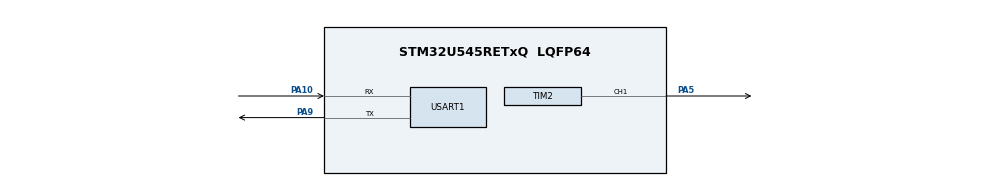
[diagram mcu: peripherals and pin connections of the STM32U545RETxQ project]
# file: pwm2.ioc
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CORTEX_M33_NS.userName=CORTEX_M33
Mcu.Family=STM32U5
Mcu.Name=STM32U545RETxQ
Mcu.Package=LQFP64
NVIC.PriorityGroup=NVIC_PRIORITYGROUP_4
PA10.Mode=Asynchronous
PA10.Signal=USART1_RX
PA5.Signal=S_TIM2_CH1
PA9.Mode=Asynchronous
PA9.Signal=USART1_TX
PWR.PowerMode=PWR_SMPS_SUPPLY
ProjectManager.HeapSize=0x200
ProjectManager.StackSize=0x400
ProjectManager.TargetToolchain=STM32CubeIDE
RCC.ADCFreq_Value=16000000
RCC.DACCLockSelectionVirtual=RCC_DAC1CLKSOURCE_LSI
RCC.DACCLockSelectionVirtualString=RCC_DAC1CLKSOURCE_LSI
RCC.EPOD_VALUE=4000000
RCC.HSE_VALUE=16000000
RCC.HSI48_VALUE=48000000
RCC.HSI_VALUE=16000000
RCC.LSE_VALUE=32768
RCC.LSIDIV_VALUE=32000
RCC.MSI_VALUE=4000000
RCC.USBFreq_Value=48000000
RCC.VCOOutputFreq_Value=516000000
SH.S_TIM2_CH1.0=TIM2_CH1,PWM Generation1 CH1
TIM2.AutoReloadPreload=TIM_AUTORELOAD_PRELOAD_DISABLE
TIM2.Channel-PWM\ Generation1\ CH1=TIM_CHANNEL_1
TIM2.PeriodNoDither=1000-1
TIM2.Prescaler=4-1
TIM2.PulseNoDither_1=0
USART1.VirtualMode-Asynchronous=VM_ASYNC
VP_ICACHE_VS_ICACHE.Mode=DirectMappedCache
VP_LPBAMQUEUE_VS_QUEUE.Mode=QUEUEMODE
VP_MEMORYMAP_VS_MEMORYMAP.Mode=CurAppReg
VP_NUCLEO-U545RE-Q_VS_BSP_COMMON.Mode=COMMON
VP_PWR_VS_LPOM.Mode=PowerOptimisation
VP_PWR_VS_SECSignals.Mode=Security/Privilege
VP_TIM2_VS_ClockSourceINT.Mode=Internal
board=NUCLEO-U545RE-Q

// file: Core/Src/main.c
/* USER CODE BEGIN Header */
/**
  ******************************************************************************
  * @file           : main.c
  * @brief          : Main program body
  ******************************************************************************
  * @attention
  *
  * Copyright (c) 2026 STMicroelectronics.
  * All rights reserved.
  *
  * This software is licensed under terms that can be found in the LICENSE file
  * in the root directory of this software component.
  * If no LICENSE file comes with this software, it is provided AS-IS.
  *
  ******************************************************************************
  */
/* USER CODE END Header */
#include "main.h"

TIM_HandleTypeDef htim2;

UART_HandleTypeDef huart1;

void SystemClock_Config(void);
static void SystemPower_Config(void);
static void MX_GPIO_Init(void);
static void MX_ICACHE_Init(void);
static void MX_USART1_UART_Init(void);
static void MX_TIM2_Init(void);

int main(void)
{

  /* MCU Configuration--------------------------------------------------------*/

  /* Reset of all peripherals, Initializes the Flash interface and the Systick. */
  HAL_Init();

  /* Configure the System Power */
  SystemPower_Config();

  /* Configure the system clock */
  SystemClock_Config();

  /* Initialize all configured peripherals */
  MX_GPIO_Init();
  MX_ICACHE_Init();
  MX_USART1_UART_Init();
  MX_TIM2_Init();
  /* USER CODE BEGIN 2 */
  HAL_TIM_PWM_Start(&htim2, TIM_CHANNEL_1);  // start PWM
  uint32_t maxPulse = htim2.Init.Period;  // = 999

  /* USER CODE END 2 */

  /* Infinite loop */
  /* USER CODE BEGIN WHILE */
  while (1)
  {
	  for (uint32_t pulse = 0; pulse <= maxPulse; pulse++)
	  {
		  __HAL_TIM_SET_COMPARE(&htim2, TIM_CHANNEL_1, pulse);
		  HAL_Delay(1);  // 1 ms per step → fade di ~1 s
	  }

    /* USER CODE END WHILE */

  }
}

void SystemClock_Config(void)
{
  RCC_OscInitTypeDef RCC_OscInitStruct = {0};
  RCC_ClkInitTypeDef RCC_ClkInitStruct = {0};

  /** Configure the main internal regulator output voltage
  */
  if (HAL_PWREx_ControlVoltageScaling(PWR_REGULATOR_VOLTAGE_SCALE4) != HAL_OK)
  {
    Error_Handler();
  }

  /** Initializes the CPU, AHB and APB buses clocks
  */
  RCC_OscInitStruct.OscillatorType = RCC_OSCILLATORTYPE_MSI;
  RCC_OscInitStruct.MSIState = RCC_MSI_ON;
  RCC_OscInitStruct.MSICalibrationValue = RCC_MSICALIBRATION_DEFAULT;
  RCC_OscInitStruct.MSIClockRange = RCC_MSIRANGE_4;
  RCC_OscInitStruct.PLL.PLLState = RCC_PLL_NONE;
  if (HAL_RCC_OscConfig(&RCC_OscInitStruct) != HAL_OK)
  {
    Error_Handler();
  }

  /** Initializes the CPU, AHB and APB buses clocks
  */
  RCC_ClkInitStruct.ClockType = RCC_CLOCKTYPE_HCLK|RCC_CLOCKTYPE_SYSCLK
                              |RCC_CLOCKTYPE_PCLK1|RCC_CLOCKTYPE_PCLK2
                              |RCC_CLOCKTYPE_PCLK3;
  RCC_ClkInitStruct.SYSCLKSource = RCC_SYSCLKSOURCE_MSI;
  RCC_ClkInitStruct.AHBCLKDivider = RCC_SYSCLK_DIV1;
  RCC_ClkInitStruct.APB1CLKDivider = RCC_HCLK_DIV1;
  RCC_ClkInitStruct.APB2CLKDivider = RCC_HCLK_DIV1;
  RCC_ClkInitStruct.APB3CLKDivider = RCC_HCLK_DIV1;

  if (HAL_RCC_ClockConfig(&RCC_ClkInitStruct, FLASH_LATENCY_0) != HAL_OK)
  {
    Error_Handler();
  }
}

/**
  * @brief Power Configuration
  * @retval None
  */
static void SystemPower_Config(void)
{

  /*
   * Switch to SMPS regulator instead of LDO
   */
  if (HAL_PWREx_ConfigSupply(PWR_SMPS_SUPPLY) != HAL_OK)
  {
    Error_Handler();
  }
}

static void MX_ICACHE_Init(void)
{

  /** Enable instruction cache in 1-way (direct mapped cache)
  */
  if (HAL_ICACHE_ConfigAssociativityMode(ICACHE_1WAY) != HAL_OK)
  {
    Error_Handler();
  }
  if (HAL_ICACHE_Enable() != HAL_OK)
  {
    Error_Handler();
  }

}

static void MX_TIM2_Init(void)
{

  TIM_ClockConfigTypeDef sClockSourceConfig = {0};
  TIM_MasterConfigTypeDef sMasterConfig = {0};
  TIM_OC_InitTypeDef sConfigOC = {0};

  htim2.Instance = TIM2;
  htim2.Init.Prescaler = 4-1;
  htim2.Init.CounterMode = TIM_COUNTERMODE_UP;
  htim2.Init.Period = 999;
  htim2.Init.ClockDivision = TIM_CLOCKDIVISION_DIV1;
  htim2.Init.AutoReloadPreload = TIM_AUTORELOAD_PRELOAD_DISABLE;
  if (HAL_TIM_Base_Init(&htim2) != HAL_OK)
  {
    Error_Handler();
  }
  sClockSourceConfig.ClockSource = TIM_CLOCKSOURCE_INTERNAL;
  if (HAL_TIM_ConfigClockSource(&htim2, &sClockSourceConfig) != HAL_OK)
  {
    Error_Handler();
  }
  if (HAL_TIM_PWM_Init(&htim2) != HAL_OK)
  {
    Error_Handler();
  }
  sMasterConfig.MasterOutputTrigger = TIM_TRGO_RESET;
  sMasterConfig.MasterSlaveMode = TIM_MASTERSLAVEMODE_DISABLE;
  if (HAL_TIMEx_MasterConfigSynchronization(&htim2, &sMasterConfig) != HAL_OK)
  {
    Error_Handler();
  }
  sConfigOC.OCMode = TIM_OCMODE_PWM1;
  sConfigOC.Pulse = 9999;
  sConfigOC.OCPolarity = TIM_OCPOLARITY_HIGH;
  sConfigOC.OCFastMode = TIM_OCFAST_DISABLE;
  if (HAL_TIM_PWM_ConfigChannel(&htim2, &sConfigOC, TIM_CHANNEL_1) != HAL_OK)
  {
    Error_Handler();
  }
  HAL_TIM_MspPostInit(&htim2);

}

static void MX_USART1_UART_Init(void)
{

  huart1.Instance = USART1;
  huart1.Init.BaudRate = 115200;
  huart1.Init.WordLength = UART_WORDLENGTH_8B;
  huart1.Init.StopBits = UART_STOPBITS_1;
  huart1.Init.Parity = UART_PARITY_NONE;
  huart1.Init.Mode = UART_MODE_TX_RX;
  huart1.Init.HwFlowCtl = UART_HWCONTROL_NONE;
  huart1.Init.OverSampling = UART_OVERSAMPLING_16;
  huart1.Init.OneBitSampling = UART_ONE_BIT_SAMPLE_DISABLE;
  huart1.Init.ClockPrescaler = UART_PRESCALER_DIV1;
  huart1.AdvancedInit.AdvFeatureInit = UART_ADVFEATURE_NO_INIT;
  if (HAL_UART_Init(&huart1) != HAL_OK)
  {
    Error_Handler();
  }
  if (HAL_UARTEx_SetTxFifoThreshold(&huart1, UART_TXFIFO_THRESHOLD_1_8) != HAL_OK)
  {
    Error_Handler();
  }
  if (HAL_UARTEx_SetRxFifoThreshold(&huart1, UART_RXFIFO_THRESHOLD_1_8) != HAL_OK)
  {
    Error_Handler();
  }
  if (HAL_UARTEx_DisableFifoMode(&huart1) != HAL_OK)
  {
    Error_Handler();
  }

}

static void MX_GPIO_Init(void)
{

  /* GPIO Ports Clock Enable */
  __HAL_RCC_GPIOA_CLK_ENABLE();

}

void Error_Handler(void)
{
  __disable_irq();
  while (1)
  {
  }
}
